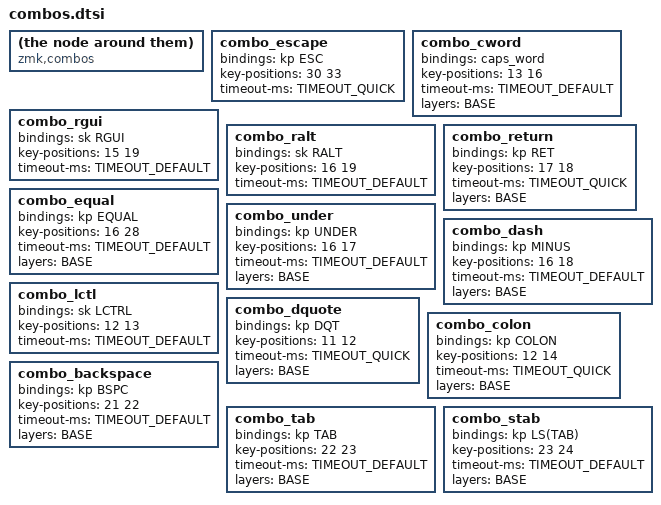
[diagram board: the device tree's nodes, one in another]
/*                KEY POSITIONS

  ╭────────────────────╮ ╭────────────────────╮
  │  0   1   2   3   4 │ │  5   6   7   8   9 │
  │ 10  11  12  13  14 │ │ 15  16  17  18  19 │
  │ 20  21  22  23  24 │ │ 25  26  27  28  29 │
  ╰───────────╮ 30  31 │ │ 32  33 ╭───────────╯
              ╰────────╯ ╰────────╯            */

compatible = "zmk,combos";

/* Multi-Hand */
combo_escape {
  bindings = <&kp ESC>;
  key-positions = <30 33>;
  timeout-ms = <TIMEOUT_QUICK>;
};

combo_cword {
  bindings = <&caps_word>;
  key-positions = <13 16>;
  timeout-ms = <TIMEOUT_DEFAULT>;
  layers = <BASE>;
};

/* Right */
combo_rgui {
  bindings = <&sk RGUI>;
  key-positions = <15 19>;
  timeout-ms = <TIMEOUT_DEFAULT>;
};
combo_ralt {
  bindings = <&sk RALT>;
  key-positions = <16 19>;
  timeout-ms = <TIMEOUT_DEFAULT>;
};
combo_return {
  bindings = <&kp RET>;
  key-positions = <17 18>;
  timeout-ms = <TIMEOUT_QUICK>;
  layers = <BASE>;
};
combo_equal {
  bindings = <&kp EQUAL>;
  key-positions = <16 28>;
  timeout-ms = <TIMEOUT_DEFAULT>;
  layers = <BASE>;
};
combo_under {
  bindings = <&kp UNDER>;
  key-positions = <16 17>;
  timeout-ms = <TIMEOUT_DEFAULT>;
  layers = <BASE>;
};
combo_dash {
  bindings = <&kp MINUS>;
  key-positions = <16 18>;
  timeout-ms = <TIMEOUT_DEFAULT>;
  layers = <BASE>;
};

/* Left */
combo_lctl {
  bindings = <&sk LCTRL>;
  key-positions = <12 13>;
  timeout-ms = <TIMEOUT_DEFAULT>;
};
combo_dquote {
  bindings = <&kp DQT>;
  key-positions = <11 12>;
  timeout-ms = <TIMEOUT_QUICK>;
  layers = <BASE>;
};
combo_colon {
  bindings = <&kp COLON>;
  key-positions = <12 14>;
  timeout-ms = <TIMEOUT_QUICK>;
  layers = <BASE>;
};
combo_backspace {
  bindings = <&kp BSPC>;
  key-positions = <21 22>;
  timeout-ms = <TIMEOUT_DEFAULT>;
  layers = <BASE>;
};
combo_tab {
  bindings = <&kp TAB>;
  key-positions = <22 23>;
  timeout-ms = <TIMEOUT_DEFAULT>;
  layers = <BASE>;
};
combo_stab {
  bindings = <&kp LS(TAB)>;
  key-positions = <23 24>;
  timeout-ms = <TIMEOUT_DEFAULT>;
  layers = <BASE>;
};
